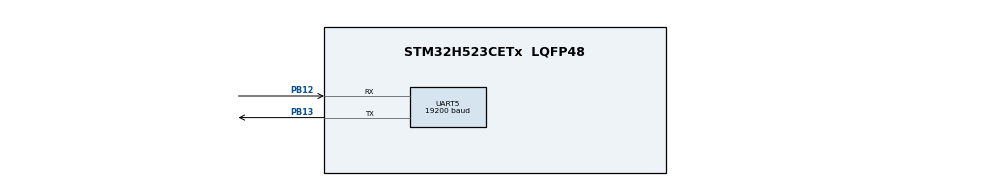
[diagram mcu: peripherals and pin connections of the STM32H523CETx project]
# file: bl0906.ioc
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BOOTPATH.BootPathName=LEGACY
BOOTPATH.UserSelectedBootPath=LEGACY
CORTEX_M33_NS.Number-Cortex_Memory_Protection_Unit_Region0_OTP_RO_AREAS_Settings=MPU_REGION_NUMBER0
CORTEX_M33_NS.default_mode_Activation=1
CORTEX_M33_NS.userName=CORTEX_M33
Mcu.Family=STM32H5
Mcu.Name=STM32H523CETx
Mcu.Package=LQFP48
NVIC.PriorityGroup=NVIC_PRIORITYGROUP_4
PA13(JTMS/SWDIO).Mode=Serial_Wire
PA13(JTMS/SWDIO).Signal=DEBUG_JTMS-SWDIO
PA14(JTCK/SWCLK).Mode=Serial_Wire
PA14(JTCK/SWCLK).Signal=DEBUG_JTCK-SWCLK
PB12.Mode=Asynchronous
PB12.Signal=UART5_RX
PB13.Mode=Asynchronous
PB13.Signal=UART5_TX
PH0-OSC_IN(PH0).Mode=HSE-External-Oscillator
PH0-OSC_IN(PH0).Signal=RCC_OSC_IN
PH1-OSC_OUT(PH1).Mode=HSE-External-Oscillator
PH1-OSC_OUT(PH1).Signal=RCC_OSC_OUT
ProjectManager.HeapSize=0x200
ProjectManager.StackSize=0x400
ProjectManager.TargetToolchain=STM32CubeIDE
RCC.ADCFreq_Value=250000000
RCC.AHBFreq_Value=250000000
RCC.APB1Freq_Value=250000000
RCC.APB1TimFreq_Value=250000000
RCC.APB2Freq_Value=250000000
RCC.APB2TimFreq_Value=250000000
RCC.APB3Freq_Value=250000000
RCC.CSI_VALUE=4000000
RCC.CortexFreq_Value=250000000
RCC.EPOD_VALUE=4000000
RCC.HCLKFreq_Value=250000000
RCC.HSE_VALUE=8000000
RCC.HSI48_VALUE=48000000
RCC.HSI_VALUE=64000000
RCC.LSE_VALUE=32768
RCC.LSIRC_VALUE=32000
RCC.PLL2FRACN=0
RCC.PLL2Source=RCC_PLL2_SOURCE_HSE
RCC.PLL3FRACN=0
RCC.PLLFRACN=0
RCC.PLLN=125
RCC.SYSCLKFreq_VALUE=250000000
RCC.SYSCLKSource=RCC_SYSCLKSOURCE_PLLCLK
RCC.USBFreq_Value=48000000
RCC.VCOOutputFreq_Value=500000000
UART5.BaudRate=19200
VP_BOOTPATH_VS_BOOTPATH.Mode=BP_Activate
VP_CORTEX_M33_NS_VS_Hclk.Mode=Hclk_Mode
VP_ICACHE_VS_ICACHE.Mode=DirectMappedCache
VP_MEMORYMAP_VS_MEMORYMAP.Mode=CurAppReg
VP_PWR_VS_LPOM.Mode=PowerOptimisation
VP_PWR_VS_SECSignals.Mode=Security/Privilege
board=custom

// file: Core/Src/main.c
/* USER CODE BEGIN Header */
/**
  ******************************************************************************
  * @file           : main.c
  * @brief          : Main program body
  ******************************************************************************
  * @attention
  *
  * Copyright (c) 2026 STMicroelectronics.
  * All rights reserved.
  *
  * This software is licensed under terms that can be found in the LICENSE file
  * in the root directory of this software component.
  * If no LICENSE file comes with this software, it is provided AS-IS.
  *
  ******************************************************************************
  */
/* USER CODE END Header */
#include "main.h"
#include "icache.h"
#include "usart.h"
#include "gpio.h"

/* USER CODE BEGIN Includes */
#include "bl0906.h"
#include <stdio.h>
/* USER CODE END Includes */

/* USER CODE BEGIN PV */
volatile uint32_t g_ms_tick = 0;
BL0906_Data_t g_bl0906 = {0};
/* USER CODE END PV */

void SystemClock_Config(void);
static void MPU_Config(void);

int main(void)
{

  /* MCU Configuration--------------------------------------------------------*/

  /* Reset of all peripherals, Initializes the Flash interface and the Systick. */

  /* MPU Configuration--------------------------------------------------------*/
  MPU_Config();

  /* System interrupt init*/
  NVIC_SetPriorityGrouping(NVIC_PRIORITYGROUP_4);

  /* SysTick_IRQn interrupt configuration */
  NVIC_SetPriority(SysTick_IRQn, NVIC_EncodePriority(NVIC_GetPriorityGrouping(),15, 0));

  /* Configure the system clock */
  SystemClock_Config();

  /* Initialize all configured peripherals */
  MX_GPIO_Init();
  MX_ICACHE_Init();
  MX_UART5_Init();
  /* USER CODE BEGIN 2 */
  /* Inisialisasi driver BL0906 pada UART5 (LL) */
  BL0906_Init(UART5);
  /* USER CODE END 2 */

  /* Infinite loop */
  /* USER CODE BEGIN WHILE */
  while (1)
  {
    /* Membaca seluruh data sensor BL0906:
     * - Tegangan (V)
     * - Arus CH1..CH6 (A)
     * - Daya CH1..CH6 (W) & Total Daya (W)
     * - Energi CH1..CH6 (kWh) & Total Energi (kWh)
     * - Frekuensi Listrik (Hz)
     * - Suhu Chip (°C)
     *
     * Data dapat dipantau langsung secara real-time di tab "Live Expressions"
     * STM32CubeIDE dengan mengetik: g_bl0906
     */
    BL0906_ReadAll(&g_bl0906);

    /* Polling tiap 1 detik menggunakan LL_mDelay */
    LL_mDelay(1000);
    /* USER CODE END WHILE */

  }
}

void SystemClock_Config(void)
{
  LL_FLASH_SetLatency(LL_FLASH_LATENCY_5);
  while(LL_FLASH_GetLatency()!= LL_FLASH_LATENCY_5)
  {
  }

  LL_PWR_SetRegulVoltageScaling(LL_PWR_REGU_VOLTAGE_SCALE0);
  while (LL_PWR_IsActiveFlag_VOS() == 0)
  {
  }
  LL_RCC_CSI_Enable();

   /* Wait till CSI is ready */
  while(LL_RCC_CSI_IsReady() != 1)
  {
  }

  LL_RCC_CSI_SetCalibTrimming(32);
  LL_RCC_PLL1_SetSource(LL_RCC_PLL1SOURCE_CSI);
  LL_RCC_PLL1_SetVCOInputRange(LL_RCC_PLLINPUTRANGE_4_8);
  LL_RCC_PLL1_SetVCOOutputRange(LL_RCC_PLLVCORANGE_WIDE);
  LL_RCC_PLL1_SetM(1);
  LL_RCC_PLL1_SetN(125);
  LL_RCC_PLL1_SetP(2);
  LL_RCC_PLL1_SetQ(2);
  LL_RCC_PLL1_SetR(2);
  LL_RCC_PLL1P_Enable();
  LL_RCC_PLL1_Enable();

   /* Wait till PLL is ready */
  while(LL_RCC_PLL1_IsReady() != 1)
  {
  }

  LL_RCC_SetSysClkSource(LL_RCC_SYS_CLKSOURCE_PLL1);

   /* Wait till System clock is ready */
  while(LL_RCC_GetSysClkSource() != LL_RCC_SYS_CLKSOURCE_STATUS_PLL1)
  {
  }

  LL_RCC_SetAHBPrescaler(LL_RCC_SYSCLK_DIV_1);
  LL_RCC_SetAPB1Prescaler(LL_RCC_APB1_DIV_1);
  LL_RCC_SetAPB2Prescaler(LL_RCC_APB2_DIV_1);
  LL_RCC_SetAPB3Prescaler(LL_RCC_APB3_DIV_1);

  LL_Init1msTick(250000000);

  LL_SetSystemCoreClock(250000000);
}

 /* MPU Configuration */

void MPU_Config(void)
{

  /* Disables the MPU */
  LL_MPU_Disable();

  /** Initializes and configures the Region 0 and the memory to be protected
  */
  LL_MPU_ConfigRegion(LL_MPU_REGION_NUMBER0, LL_MPU_REGION_ALL_RO|LL_MPU_INSTRUCTION_ACCESS_DISABLE|LL_MPU_ACCESS_NOT_SHAREABLE, LL_MPU_ATTRIBUTES_NUMBER0, 0x08FFF000, 0x08FFFFFF);
  LL_MPU_EnableRegion(LL_MPU_REGION_NUMBER0);

  /** Initializes and configures the Attribute 0 and the memory to be protected
  */
  LL_MPU_ConfigAttributes(LL_MPU_ATTRIBUTES_NUMBER0, LL_MPU_NOT_CACHEABLE);
  /* Enables the MPU */
  LL_MPU_Enable(LL_MPU_CTRL_PRIVILEGED_DEFAULT);

}

void Error_Handler(void)
{
  __disable_irq();
  while (1)
  {
  }
}
